AUTOSAR XML (schema 4-2-2)
package /AUTOLIV/SoftwareComponents/CIL
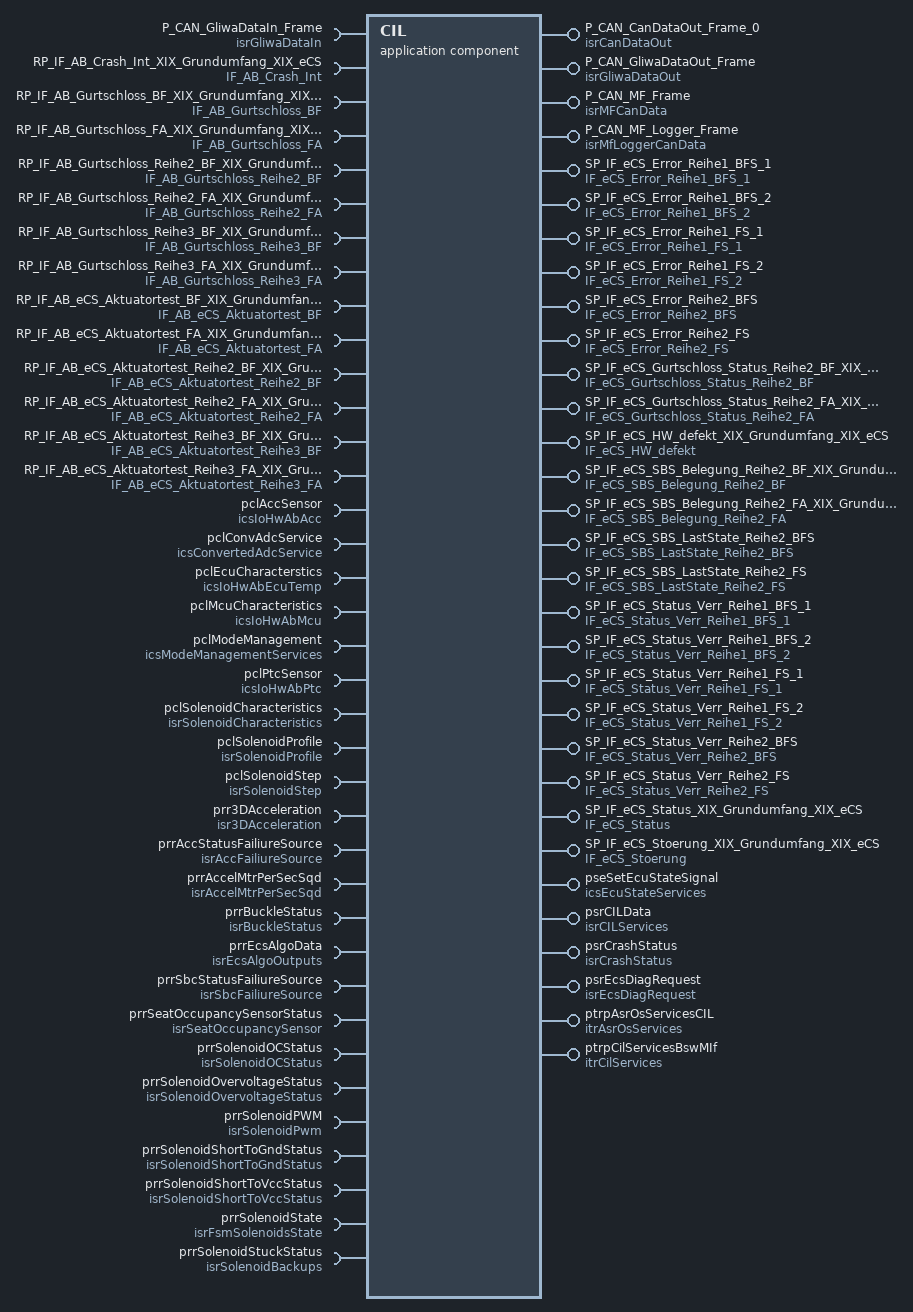
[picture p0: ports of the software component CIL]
  application sw component type CIL: category=SWC
    provide port P_CAN_CanDataOut_Frame_0: nonqueued-sender-com-spec{data-element=EcuCanDataOut, uses-end-to-end-protection=0, init-value=constant-reference=REC_APPLINIT_CAN_DATA_OUT_64}, provided-interface=isrCanDataOut  # # Architecture Element ID ARCH_SW_CIL_P_CAN_CanDataOut_Frame_0 # Description - The runnable shall write all the content of the CAN signals belonging to the eCS Dev Frame - The runnable shall read from the Application the followig data and send them on the CAN bus: - Acceleration on X,Y,Z axis in g - Acceleration on X,Y,Z axis in m/s^2 - eCS Algorithm Decision - Ball Position in mm - Selected Profile[for each solenoid] - Selected step [for each solenoid] - Solenoid state [for each solenoid] - Solenoid confirmation status [for each solenoid] - Buckle Status [for each solenoid] - Lock Execution Counter [for each solenoid] - Unlock Execution Counter [for each solenoid] - Unlock Confirmed Execution Counter [for each solenoid] - Seat Occupancy Status [for each seat] - Warm reset counter # Data Flow ## Inputs: - See data above ## Outputs - See data above # Linked Runnable - CIL_runAppliToCAN # Traceability DOM_eCS_TF_B_114; DOM_eCS_TF_B_117; DOM_eCS_TF_B_119; DOM_eCS_TF_B_124; DOM_eCS_TF_B_126; DOM_eCS_TF_B_129; DOM_eCS_TF_B_135; DOM_eCS_TF_B_137; DOM_eCS_TF_B_139; DOM_eCS_TF_B_141; DOM_eCS_TF_B_143; DOM_eCS_TF_B_145; DOM_eCS_TF_B_149; DOM_eCS_TF_B_152; DOM_eCS_TF_B_155; DOM_eCS_TF_B_157; DOM_eCS_TF_B_159; DOM_eCS_TF_B_161; DOM_eCS_TF_B_163; DOM_eCS_TF_B_165; DOM_eCS_TF_B_169; DOM_eCS_TF_B_171; DOM_eCS_TF_B_173; DOM_eCS_TF_B_175; DOM_eCS_TF_B_177; DOM_eCS_TF_B_178; DOM_eCS_TF_B_179; DOM_eCS_TF_B_545; DOM_eCS_TF_B_560; DOM_eCS_TF_B_557; DOM_eCS_TF_B_554; DOM_eCS_TF_B_551; DOM_eCS_TF_B_548; DOM_eCS_TF_B_563; DOM_eCS_TF_B_579; DOM_eCS_TF_B_575; DOM_eCS_TF_B_572; DOM_eCS_TF_B_569; DOM_eCS_TF_B_566; DOM_eCS_TF_B_581; DOM_eCS_TF_B_596; DOM_eCS_TF_B_593; DOM_eCS_TF_B_590; DOM_eCS_TF_B_587; DOM_eCS_TF_B_584; DOM_eCS_TF_B_614; DOM_eCS_TF_B_611; DOM_eCS_TF_B_608; DOM_eCS_TF_B_605; DOM_eCS_TF_B_602; DOM_eCS_TF_B_599; DOM_eCS_TF_B_617
    require port P_CAN_GliwaDataIn_Frame: nonqueued-receiver-com-spec{data-element=GliwaCanDataIn, init-value=constant-reference=REC_APPLINIT_CAN_DATA}, required-interface=isrGliwaDataIn  # # Architecture Element ID ARCH_SW_CIL_P_CAN_GliwaDataIn_Frame # Description - Interface used to receive {Data on the CAN bus} from the T1 Gliwa suite, if enabled by pre-processor # Data Flow ## Inputs: - ## Outputs - {Data on the CAN bus} # Linked Runnable - CIL_runManageMF # Traceability
    provide port P_CAN_GliwaDataOut_Frame: nonqueued-sender-com-spec{data-element=GliwaCanDataOut, uses-end-to-end-protection=0, init-value=constant-reference=REC_APPLINIT_CAN_DATA_OUT_64}, provided-interface=isrGliwaDataOut  # # Architecture Element ID ARCH_SW_CIL_P_CAN_GliwaDataOut_Frame # Description - The runnable shall be called by the T1 Gliwa library with data that will be sent on the CAN bus, if the pre-processor option is enabled # Data Flow ## Inputs: - ## Outputs - See data above # Linked Runnable - CIL_Gliwa_TXNotification # Traceability
    provide port P_CAN_MF_Frame: nonqueued-sender-com-spec{data-element=stMFData, uses-end-to-end-protection=0, init-value=constant-reference=REC_APPLINIT_CAN_DATA_OUT_64}, provided-interface=isrMFCanData  # P_CAN_MeasurementFrame_Frame | # Architecture Element ID ARCH_SW_CIL_P_CAN_MF_Frame # Description - The runnable shall write all the content of the CAN signals belonging to the eCS Measurement Frame - The runnable shall read from the Application the followig data and send them on the CAN bus: - Multiplexed Block 01: - MCU sensor temperature - ACC sensor temperature - PTC sensor temperature - ECU temperature - PWM applied[for each solenoid] - Voltage measured [for each solenoid] - Current measured mA[for each solenoid] - Solenoid temperature [for each solenoid] - KL30 voltage - Solenoid OC Status[for each solenoid] - Solenoid Short to VBAT Status[for each solenoid] - Solenoid Short to GND Status[for each solenoid] - Solenoid Actuator Blocked Status[for each solenoid] - Accelerometer Error Register Content - SBC Error Register Content - Multiplexed Block 02: - Dem Event Status(for each available event) - Multiplexed Block 03: - Content of RAM memory as configured in the NVP_au32RequestedRamAddressArray, NVP_au8RequestedRamSizeArray variables # Data Flow ## Inputs: - See data above ## Outputs - See data above # Linked Runnable - CIL_runManageMF # Traceability DOM_eCS_TF_B_220; DOM_eCS_TF_B_222; DOM_eCS_TF_B_226; DOM_eCS_TF_B_229; DOM_eCS_TF_B_232; DOM_eCS_TF_B_235; DOM_eCS_TF_B_238; DOM_eCS_TF_B_241; DOM_eCS_TF_B_244; DOM_eCS_TF_B_247; DOM_eCS_TF_B_250; DOM_eCS_TF_B_253; DOM_eCS_TF_B_256; DOM_eCS_TF_B_259; DOM_eCS_TF_B_262; DOM_eCS_TF_B_265; DOM_eCS_TF_B_268; DOM_eCS_TF_B_271; DOM_eCS_TF_B_274; DOM_eCS_TF_B_277; DOM_eCS_TF_B_280; DOM_eCS_TF_B_283; DOM_eCS_TF_B_286; DOM_eCS_TF_B_289; DOM_eCS_TF_B_292; DOM_eCS_TF_B_295; DOM_eCS_TF_B_298; DOM_eCS_TF_B_301; DOM_eCS_TF_B_304; DOM_eCS_TF_B_307; DOM_eCS_TF_B_312; DOM_eCS_TF_B_315; DOM_eCS_TF_B_348; DOM_eCS_TF_B_345; DOM_eCS_TF_B_342; DOM_eCS_TF_B_339; DOM_eCS_TF_B_336; DOM_eCS_TF_B_333; DOM_eCS_TF_B_330; DOM_eCS_TF_B_327; DOM_eCS_TF_B_324; DOM_eCS_TF_B_321; DOM_eCS_TF_B_318; DOM_eCS_TF_B_351; DOM_eCS_TF_B_354
    provide port P_CAN_MF_Logger_Frame: provided-interface=isrMfLoggerCanData  # # Architecture Element ID ARCH_SW_CIL_P_CAN_MF_Logger_Frame # Description - The runnable shall be called when an ECU state change is detected - When an ECU state change is detected then a single frame shall be sent on the CAN bus with the value of the current ECU state # Data Flow ## Inputs: - ## Outputs - {ECU State} # Linked Runnable - CIL_updateCurrentEcuState # Traceability
    13 x require port:
      RP_IF_AB_Crash_Int_XIX_Grundumfang_XIX_eCS: required-interface=IF_AB_Crash_Int  # # Architecture Element ID ARCH_SW_CIL_RP_IF_AB_Crash_Int_XIX_Grundumfang_XIX_eCS # Description - Interface used to receive the crash status from the CAN bus # Data Flow ## Inputs: ## Outputs - {Crash Status} # Linked Runnable - CIL_runAppliToCAN # Traceability DOM_eCS_TF_B_396; DOM_eCS_TF_B_540, DOM_eCS_TF_R_20
      RP_IF_AB_Gurtschloss_BF_XIX_Grundumfang_XIX_eCS: required-interface=IF_AB_Gurtschloss_BF  # # Architecture Element ID ARCH_SW_CIL_RP_IF_AB_Gurtschloss_BF_XIX_Grundumfang_XIX_eCS # Description - Interface used to read the buckle sensor status for the first row # Data Flow ## Inputs: ## Outputs - {Seat Sensor Status} - Can be: LATCHED, NOT_LATCHED, ERROR, NOT_CONFIGURED # Linked Runnable - CIL_runAppliToCAN # Traceability DOM_eCS_TF_B_400, DOM_eCS_TF_R_16
      RP_IF_AB_Gurtschloss_FA_XIX_Grundumfang_XIX_eCS: required-interface=IF_AB_Gurtschloss_FA  # # Architecture Element ID ARCH_SW_CIL_RP_IF_AB_Gurtschloss_FA_XIX_Grundumfang_XIX_eCS # Description - Interface used to read the buckle sensor status for the first row # Data Flow ## Inputs: ## Outputs - {Seat Sensor Status} - Can be: LATCHED, NOT_LATCHED, ERROR, NOT_CONFIGURED # Linked Runnable - CIL_runAppliToCAN # Traceability DOM_eCS_TF_B_403, DOM_eCS_TF_R_17
      RP_IF_AB_Gurtschloss_Reihe2_BF_XIX_Grundumfang_XIX_eCS: required-interface=IF_AB_Gurtschloss_Reihe2_BF  # N/A - Signal not used by Application
      RP_IF_AB_Gurtschloss_Reihe2_FA_XIX_Grundumfang_XIX_eCS: required-interface=IF_AB_Gurtschloss_Reihe2_FA  # N/A - Signal not used by Application
      RP_IF_AB_Gurtschloss_Reihe3_BF_XIX_Grundumfang_XIX_eCS: required-interface=IF_AB_Gurtschloss_Reihe3_BF  # N/A - Signal not used by Application
      RP_IF_AB_Gurtschloss_Reihe3_FA_XIX_Grundumfang_XIX_eCS: required-interface=IF_AB_Gurtschloss_Reihe3_FA  # N/A - Signal not used by Application
      RP_IF_AB_eCS_Aktuatortest_BF_XIX_Grundumfang_XIX_eCS: required-interface=IF_AB_eCS_Aktuatortest_BF  # # Architecture Element ID ARCH_SW_CIL_RP_IF_AB_eCS_Aktuatortest_BF_XIX_Grundumfang_XIX_eCS # Description - Interface used to read if and on demand selt-test has been requested for each solenoid - The on demand self-test for seat BF will trigger the unlock/lock for solenoids 3 && 4 # Data Flow ## Inputs: ## Outputs: - {ODST for Solenoid X} # Linked Runnable - CIL_runCANToSafetyAppli # Traceability DOM_eCS_TF_B_419, DOM_eCS_TF_R_21
      RP_IF_AB_eCS_Aktuatortest_FA_XIX_Grundumfang_XIX_eCS: required-interface=IF_AB_eCS_Aktuatortest_FA  # # Architecture Element ID ARCH_SW_CIL_RP_IF_AB_eCS_Aktuatortest_FA_XIX_Grundumfang_XIX_eCS # Description - Interface used to read if and on demand selt-test has been requested for each solenoid - The on demand self-test for seat FA will trigger the unlock/lock for solenoids 1 && 2 # Data Flow ## Inputs: ## Outputs: - {ODST for Solenoid X} # Linked Runnable - CIL_runCANToSafetyAppli # Traceability DOM_eCS_TF_B_422, DOM_eCS_TF_R_22
      RP_IF_AB_eCS_Aktuatortest_Reihe2_BF_XIX_Grundumfang_XIX_eCS: required-interface=IF_AB_eCS_Aktuatortest_Reihe2_BF  # # Architecture Element ID ARCH_SW_CIL_RP_IF_AB_eCS_Aktuatortest_Reihe2_BF_XIX_Grundumfang_XIX_eCS # Description - Interface used to read if and on demand selt-test has been requested for each solenoid - The on demand self-test for seat BF Reihe 2 will trigger the unlock/lock for solenoids 6 # Data Flow ## Inputs: ## Outputs: - {ODST for Solenoid X} # Linked Runnable - CIL_runCANToSafetyAppli # Traceability DOM_eCS_TF_B_425, DOM_eCS_TF_R_23
      RP_IF_AB_eCS_Aktuatortest_Reihe2_FA_XIX_Grundumfang_XIX_eCS: required-interface=IF_AB_eCS_Aktuatortest_Reihe2_FA  # # Architecture Element ID ARCH_SW_CIL_RP_IF_AB_eCS_Aktuatortest_Reihe2_FA_XIX_Grundumfang_XIX_eCS # Description - Interface used to read if and on demand selt-test has been requested for each solenoid - The on demand self-test for seat FA Reihe 2 will trigger the unlock/lock for solenoids 5 # Data Flow ## Inputs: ## Outputs: - {ODST for Solenoid X} # Linked Runnable - CIL_runCANToSafetyAppli # Traceability DOM_eCS_TF_B_428, DOM_eCS_TF_R_24
      RP_IF_AB_eCS_Aktuatortest_Reihe3_BF_XIX_Grundumfang_XIX_eCS: required-interface=IF_AB_eCS_Aktuatortest_Reihe3_BF  # N/A - Signal not used by Application
      RP_IF_AB_eCS_Aktuatortest_Reihe3_FA_XIX_Grundumfang_XIX_eCS: required-interface=IF_AB_eCS_Aktuatortest_Reihe3_FA  # N/A - Signal not used by Application
    21 x provide port:
      SP_IF_eCS_Error_Reihe1_BFS_1: provided-interface=IF_eCS_Error_Reihe1_BFS_1  # # Architecture Element ID ARCH_SW_CIL_SP_IF_eCS_Error_Reihe1_BFS_1 # Description - The runnable shall read the mode status coresponding to SOLENOID_X_DISABLED where the solenoid is the first one on the front row seat BF - The runnable shall read the error status of the OPEN_CIRCUIT error on the corresponding solenoid - The runnable shall read the error status of the SHORT_TO_GND error on the corresponding solenoid - The runnable shall read the error status of the SHORT_TO_VBAT error on the corresponding solenoid - The runnable shall read the error status of the ACTUATOR_BLOCKED error on the corresponding solenoid - If the SOLENOID_X_DISABLED mode is set and OPEN_CIRCUIT error is set for the corresponding solenoid then the CAN signal shall be set to OPEN_CIRCUIT - If the SOLENOID_X_DISABLED mode is set and SHORT_TO_GND error is set for the corresponding solenoid then the CAN signal shall be set to SHORT_TO_GND - If the SOLENOID_X_DISABLED mode is set and SHORT_TO_VBAT error is set for the corresponding solenoid then the CAN signal shall be set to SHORT_TO_VBAT - If the SOLENOID_X_DISABLED mode is set and ACTUATOR_BLOCKED error is set for the corresponding solenoid then the CAN signal shall be set to ACTUATOR_BLOCKED # Data Flow ## Inputs: - {Mode Status} - {OC Status for Solenoid X} - {Short to VBAT Status for Solenoid X} - {Short to GND Status for Solenoid X} - {Actuator Blocked Status for Solenoid X} ## Outputs - {Error Status} - Can be: NO_ERROR/SHORT_TO_GND/SHORT_TO_VBAT/OPEN_CIRCUIT/ACTUATOR_BLOCKED # Note - ACTUATOR_BLOCKED = ACTUATOR_COIL_ERROR # Linked Runnable - CIL_runAppliToCAN # Traceability DOM_eCS_TF_B_1085
      SP_IF_eCS_Error_Reihe1_BFS_2: provided-interface=IF_eCS_Error_Reihe1_BFS_2  # # Architecture Element ID ARCH_SW_CIL_SP_IF_eCS_Error_Reihe1_BFS_2 # Description - The runnable shall read the mode status coresponding to SOLENOID_X_DISABLED where the solenoid is the second one on the front row seat BF - The runnable shall read the error status of the OPEN_CIRCUIT error on the corresponding solenoid - The runnable shall read the error status of the SHORT_TO_GND error on the corresponding solenoid - The runnable shall read the error status of the SHORT_TO_VBAT error on the corresponding solenoid - The runnable shall read the error status of the ACTUATOR_BLOCKED error on the corresponding solenoid - If the SOLENOID_X_DISABLED mode is set and OPEN_CIRCUIT error is set for the corresponding solenoid then the CAN signal shall be set to OPEN_CIRCUIT - If the SOLENOID_X_DISABLED mode is set and SHORT_TO_GND error is set for the corresponding solenoid then the CAN signal shall be set to SHORT_TO_GND - If the SOLENOID_X_DISABLED mode is set and SHORT_TO_VBAT error is set for the corresponding solenoid then the CAN signal shall be set to SHORT_TO_VBAT - If the SOLENOID_X_DISABLED mode is set and ACTUATOR_BLOCKED error is set for the corresponding solenoid then the CAN signal shall be set to ACTUATOR_BLOCKED # Data Flow ## Inputs: - {Mode Status} - {OC Status for Solenoid X} - {Short to VBAT Status for Solenoid X} - {Short to GND Status for Solenoid X} - {Actuator Blocked Status for Solenoid X} ## Outputs - {Error Status} - Can be: NO_ERROR/SHORT_TO_GND/SHORT_TO_VBAT/OPEN_CIRCUIT/ACTUATOR_BLOCKED # Note - ACTUATOR_BLOCKED = ACTUATOR_COIL_ERROR # Linked Runnable - CIL_runAppliToCAN # Traceability DOM_eCS_TF_B_1089
      SP_IF_eCS_Error_Reihe1_FS_1: provided-interface=IF_eCS_Error_Reihe1_FS_1  # # Architecture Element ID ARCH_SW_CIL_SP_IF_eCS_Error_Reihe1_FS_1 # Description - The runnable shall read the mode status coresponding to SOLENOID_X_DISABLED where the solenoid is the first one on the front row seat FA - The runnable shall read the error status of the OPEN_CIRCUIT error on the corresponding solenoid - The runnable shall read the error status of the SHORT_TO_GND error on the corresponding solenoid - The runnable shall read the error status of the SHORT_TO_VBAT error on the corresponding solenoid - The runnable shall read the error status of the ACTUATOR_BLOCKED error on the corresponding solenoid - If the SOLENOID_X_DISABLED mode is set and OPEN_CIRCUIT error is set for the corresponding solenoid then the CAN signal shall be set to OPEN_CIRCUIT - If the SOLENOID_X_DISABLED mode is set and SHORT_TO_GND error is set for the corresponding solenoid then the CAN signal shall be set to SHORT_TO_GND - If the SOLENOID_X_DISABLED mode is set and SHORT_TO_VBAT error is set for the corresponding solenoid then the CAN signal shall be set to SHORT_TO_VBAT - If the SOLENOID_X_DISABLED mode is set and ACTUATOR_BLOCKED error is set for the corresponding solenoid then the CAN signal shall be set to ACTUATOR_BLOCKED # Data Flow ## Inputs: - {Mode Status} - {OC Status for Solenoid X} - {Short to VBAT Status for Solenoid X} - {Short to GND Status for Solenoid X} - {Actuator Blocked Status for Solenoid X} ## Outputs - {Error Status} - Can be: NO_ERROR/SHORT_TO_GND/SHORT_TO_VBAT/OPEN_CIRCUIT/ACTUATOR_BLOCKED # Note - ACTUATOR_BLOCKED = ACTUATOR_COIL_ERROR # Linked Runnable - CIL_runAppliToCAN # Traceability DOM_eCS_TF_B_1065
      SP_IF_eCS_Error_Reihe1_FS_2: provided-interface=IF_eCS_Error_Reihe1_FS_2  # # Architecture Element ID ARCH_SW_CIL_SP_IF_eCS_Error_Reihe1_FS_2 # Description - The runnable shall read the mode status coresponding to SOLENOID_X_DISABLED where the solenoid is the second one on the front row seat FA - The runnable shall read the error status of the OPEN_CIRCUIT error on the corresponding solenoid - The runnable shall read the error status of the SHORT_TO_GND error on the corresponding solenoid - The runnable shall read the error status of the SHORT_TO_VBAT error on the corresponding solenoid - The runnable shall read the error status of the ACTUATOR_BLOCKED error on the corresponding solenoid - If the SOLENOID_X_DISABLED mode is set and OPEN_CIRCUIT error is set for the corresponding solenoid then the CAN signal shall be set to OPEN_CIRCUIT - If the SOLENOID_X_DISABLED mode is set and SHORT_TO_GND error is set for the corresponding solenoid then the CAN signal shall be set to SHORT_TO_GND - If the SOLENOID_X_DISABLED mode is set and SHORT_TO_VBAT error is set for the corresponding solenoid then the CAN signal shall be set to SHORT_TO_VBAT - If the SOLENOID_X_DISABLED mode is set and ACTUATOR_BLOCKED error is set for the corresponding solenoid then the CAN signal shall be set to ACTUATOR_BLOCKED # Data Flow ## Inputs: - {Mode Status} - {OC Status for Solenoid X} - {Short to VBAT Status for Solenoid X} - {Short to GND Status for Solenoid X} - {Actuator Blocked Status for Solenoid X} ## Outputs - {Error Status} - Can be: NO_ERROR/SHORT_TO_GND/SHORT_TO_VBAT/OPEN_CIRCUIT/ACTUATOR_BLOCKED # Note - ACTUATOR_BLOCKED = ACTUATOR_COIL_ERROR # Linked Runnable - CIL_runAppliToCAN # Traceability DOM_eCS_TF_B_1087
      SP_IF_eCS_Error_Reihe2_BFS: provided-interface=IF_eCS_Error_Reihe2_BFS  # # Architecture Element ID ARCH_SW_CIL_SP_IF_eCS_Error_Reihe2_BFS # Description - The runnable shall read the mode status coresponding to SOLENOID_X_DISABLED where the solenoid is the one on the second row seat BF - The runnable shall read the error status of the OPEN_CIRCUIT error on the corresponding solenoid - The runnable shall read the error status of the SHORT_TO_GND error on the corresponding solenoid - The runnable shall read the error status of the SHORT_TO_VBAT error on the corresponding solenoid - The runnable shall read the error status of the ACTUATOR_BLOCKED error on the corresponding solenoid - If the SOLENOID_X_DISABLED mode is set and OPEN_CIRCUIT error is set for the corresponding solenoid then the CAN signal shall be set to OPEN_CIRCUIT - If the SOLENOID_X_DISABLED mode is set and SHORT_TO_GND error is set for the corresponding solenoid then the CAN signal shall be set to SHORT_TO_GND - If the SOLENOID_X_DISABLED mode is set and SHORT_TO_VBAT error is set for the corresponding solenoid then the CAN signal shall be set to SHORT_TO_VBAT - If the SOLENOID_X_DISABLED mode is set and ACTUATOR_BLOCKED error is set for the corresponding solenoid then the CAN signal shall be set to ACTUATOR_BLOCKED # Data Flow ## Inputs: - {Mode Status} - {OC Status for Solenoid X} - {Short to VBAT Status for Solenoid X} - {Short to GND Status for Solenoid X} - {Actuator Blocked Status for Solenoid X} ## Outputs - {Error Status} - Can be: NO_ERROR/SHORT_TO_GND/SHORT_TO_VBAT/OPEN_CIRCUIT/ACTUATOR_BLOCKED # Note - ACTUATOR_BLOCKED = ACTUATOR_COIL_ERROR # Linked Runnable - CIL_runAppliToCAN # Traceability DOM_eCS_TF_B_1093
      SP_IF_eCS_Error_Reihe2_FS: provided-interface=IF_eCS_Error_Reihe2_FS  # # Architecture Element ID ARCH_SW_CIL_SP_IF_eCS_Error_Reihe2_FS # Description - The runnable shall read the mode status coresponding to SOLENOID_X_DISABLED where the solenoid is the one on the second row seat FA - The runnable shall read the error status of the OPEN_CIRCUIT error on the corresponding solenoid - The runnable shall read the error status of the SHORT_TO_GND error on the corresponding solenoid - The runnable shall read the error status of the SHORT_TO_VBAT error on the corresponding solenoid - The runnable shall read the error status of the ACTUATOR_BLOCKED error on the corresponding solenoid - If the SOLENOID_X_DISABLED mode is set and OPEN_CIRCUIT error is set for the corresponding solenoid then the CAN signal shall be set to OPEN_CIRCUIT - If the SOLENOID_X_DISABLED mode is set and SHORT_TO_GND error is set for the corresponding solenoid then the CAN signal shall be set to SHORT_TO_GND - If the SOLENOID_X_DISABLED mode is set and SHORT_TO_VBAT error is set for the corresponding solenoid then the CAN signal shall be set to SHORT_TO_VBAT - If the SOLENOID_X_DISABLED mode is set and ACTUATOR_BLOCKED error is set for the corresponding solenoid then the CAN signal shall be set to ACTUATOR_BLOCKED # Data Flow ## Inputs: - {Mode Status} - {OC Status for Solenoid X} - {Short to VBAT Status for Solenoid X} - {Short to GND Status for Solenoid X} - {Actuator Blocked Status for Solenoid X} ## Outputs - {Error Status} - Can be: NO_ERROR/SHORT_TO_GND/SHORT_TO_VBAT/OPEN_CIRCUIT/ACTUATOR_BLOCKED # Note - ACTUATOR_BLOCKED = ACTUATOR_COIL_ERROR # Linked Runnable - CIL_runAppliToCAN # Traceability DOM_eCS_TF_B_1091
      SP_IF_eCS_Gurtschloss_Status_Reihe2_BF_XIX_Grundumfang_XIX_eCS: provided-interface=IF_eCS_Gurtschloss_Status_Reihe2_BF  # # Architecture Element ID ARCH_SW_CIL_SP_IF_eCS_Gurtschloss_Status_Reihe2_BF_XIX_Grundumfang_XIX_eCS # Description - The runnable shall read the buckle sensor status from the IoHwAb module - The runnable shall write the buckle sensor status for the second row on the CAN bus - If the input parameter is LATCHED then it shall transmit the LATCHED value on the CAN bus - If the input parameter is NOT_LATCHED then it shall transmit the NOT_LATCHED value on the CAN bus - If the input parameter is UNKNOWN then it shall transmit the ERROR/NOT_AVAILABLE value on the CAN bus - If the buckle sensor is not configured via the NVP_u32eCSVariant variable then the NOT_CONFIGURED value will be sent on the CAN bus # Data Flow ## Inputs: - {Buckle Sensor Status} - Can be: LATCHED, NOT_LATCHED, UNKNOWN ## Outputs - {Buckle Sensor Status} - Can be: LATCHED, NOT_LATCHED, ERROR/NOT_AVAILABLE, NOT_CONFIGURED # Linked Runnable - CIL_runAppliToCAN # Traceability DOM_eCS_TF_B_450
      SP_IF_eCS_Gurtschloss_Status_Reihe2_FA_XIX_Grundumfang_XIX_eCS: provided-interface=IF_eCS_Gurtschloss_Status_Reihe2_FA  # # Architecture Element ID ARCH_SW_CIL_SP_IF_eCS_Gurtschloss_Status_Reihe2_FA_XIX_Grundumfang_XIX_eCS # Description - The runnable shall read the buckle sensor status from the IoHwAb module - The runnable shall write the buckle sensor status for the second row on the CAN bus - If the input parameter is LATCHED then it shall transmit the LATCHED value on the CAN bus - If the input parameter is NOT_LATCHED then it shall transmit the NOT_LATCHED value on the CAN bus - If the input parameter is UNKNOWN then it shall transmit the ERROR/NOT_AVAILABLE value on the CAN bus - If the buckle sensor is not configured via the NVP_u32eCSVariant variable then the NOT_CONFIGURED value will be sent on the CAN bus # Data Flow ## Inputs: - {Buckle Sensor Status} - Can be: LATCHED, NOT_LATCHED, UNKNOWN ## Outputs - {Buckle Sensor Status} - Can be: LATCHED, NOT_LATCHED, ERROR/NOT_AVAILABLE, NOT_CONFIGURED # Linked Runnable - CIL_runAppliToCAN # Traceability DOM_eCS_TF_B_453, DOM_eCS_TF_B_497
      SP_IF_eCS_HW_defekt_XIX_Grundumfang_XIX_eCS: provided-interface=IF_eCS_HW_defekt  # # Architecture Element ID ARCH_SW_CIL_SP_IF_eCS_HW_defekt_XIX_Grundumfang_XIX_eCS # Description - The runnable shall read the mode status coresponding to KU32_ECU_SPORADIC_ERROR - If the KU32_ECU_SPORADIC_ERROR mode is set then the signal shall be set to ERROR_PRESENT - If the KU32_ECU_SPORADIC_ERROR mode is not set then the signal shall be set to ERROR_NOT_PRESENT # Data Flow ## Inputs: - {Mode Status} ## Outputs - {Error Status} - Can be: ERROR_PRESENT, ERROR_NOT_PRESENT # Linked Runnable - CIL_runAppliToCAN # Traceability DOM_eCS_TF_B_530, DOM_eCS_TF_B_458, DOM_eCS_TF_B_538, DOM_eCS_TF_B_623
      SP_IF_eCS_SBS_Belegung_Reihe2_BF_XIX_Grundumfang_XIX_eCS: provided-interface=IF_eCS_SBS_Belegung_Reihe2_BF  # # Architecture Element ID ARCH_SW_CIL_SP_IF_eCS_SBS_Belegung_Reihe2_BF_XIX_Grundumfang_XIX_eCS # Description - The runnable shall read the buckle and seat sensor status from the IoHwAb module - If the seat sensor is not configured for seat BF row 2 then the {Seat Status for Seat BF on row 2} shall be set to NICHT_VERBAUT - If the seat is occupied for seat BF row 2 then the {Seat Status for Seat BF on row 2} shall be set to BELEGT - If the seat is not occupied for seat BF row 2 then the {Seat Status for Seat BF on row 2} shall be set to NICHT_BELEGT # Data Flow ## Inputs: - {Configuration Option for Seat Sensor Seat BF row 2} - {Seat Status for Seat BF on row 2} - Can be KU8_SEAT_OCCUPANCY_NOT_DETECTED, KU8_SEAT_OCCUPANCY_DETECTED, KU8_SEAT_OCCUPANCY_UNKNOWN ## Outputs - {Seat Status for Seat BF on row 2} - Can be NICHT_BELEGT, BELEGT, KURZSCHLUSS_NACH_MASSE, NICHT_VERBAUT # Linked Runnable - CIL_runAppliToCAN # Traceability DOM_eCS_TF_B_464
      SP_IF_eCS_SBS_Belegung_Reihe2_FA_XIX_Grundumfang_XIX_eCS: provided-interface=IF_eCS_SBS_Belegung_Reihe2_FA  # # Architecture Element ID ARCH_SW_CIL_SP_IF_eCS_SBS_Belegung_Reihe2_FA_XIX_Grundumfang_XIX_eCS # Description - The runnable shall read the buckle and seat sensor status from the IoHwAb module - If the seat sensor is not configured for seat FA row 2 then the {Seat Status for Seat FA on row 2} shall be set to NICHT_VERBAUT - If the seat is occupied for seat FA row 2 then the {Seat Status for Seat FA on row 2} shall be set to BELEGT - If the seat is not occupied for seat FA row 2 then the {Seat Status for Seat FA on row 2} shall be set to NICHT_BELEGT # Data Flow ## Inputs: - {Configuration Option for Seat Sensor Seat FA row 2} - {Seat Status for Seat FA on row 2} - Can be KU8_SEAT_OCCUPANCY_NOT_DETECTED, KU8_SEAT_OCCUPANCY_DETECTED, KU8_SEAT_OCCUPANCY_UNKNOWN ## Outputs - {Seat Status for Seat FA on row 2} - Can be NICHT_BELEGT, BELEGT, KURZSCHLUSS_NACH_MASSE, NICHT_VERBAUT # Linked Runnable - CIL_runAppliToCAN # Traceability DOM_eCS_TF_B_497, DOM_eCS_TF_B_467
      SP_IF_eCS_SBS_LastState_Reihe2_BFS: provided-interface=IF_eCS_SBS_LastState_Reihe2_BFS  # # Architecture Element ID ARCH_SW_CIL_SP_IF_eCS_SBS_LastState_Reihe2_BFS # Description - The runnable shall write the last valid state of the SBS coresponding to the second seat on the second row - The runnable shall return OCCUPIED if the last valid state was OCCUPIED - The runnable shall return NOT_OCCUPIED if the last valid state was NOT_OCCUPIED - The runnable shall return INIT if the NvM was not initialized - The runnable shall return ERROR if the last valid state was SHORT_TO_GND and removable seats are not configured via the NVP_u32eCSVariant variable - The runnable shall return ERROR if the last valid state was IMPLAUSIBLE # Data Flow ## Inputs: - {Internal last valid SBS State} - {SBS configuration} ## Outputs - {Last Valid SBS Status} - Can be INIT/OCCUPIED/NOT_OCCUPIED/ERROR # Linked Runnable - CIL_runAppliToCAN # Traceability DOM_eCS_TF_B_1096, DOM_eCS_TF_B_1150
      SP_IF_eCS_SBS_LastState_Reihe2_FS: provided-interface=IF_eCS_SBS_LastState_Reihe2_FS  # # Architecture Element ID ARCH_SW_CIL_SP_IF_eCS_SBS_LastState_Reihe2_FS # Description - The runnable shall write the last valid state of the SBS coresponding to the first seat on the second row - The runnable shall return OCCUPIED if the last valid state was OCCUPIED - The runnable shall return NOT_OCCUPIED if the last valid state was NOT_OCCUPIED - The runnable shall return INIT if the NvM was not initialized - The runnable shall return ERROR if the last valid state was SHORT_TO_GND and removable seats are not configured via the NVP_u32eCSVariant variable - The runnable shall return ERROR if the last valid state was IMPLAUSIBLE # Data Flow ## Inputs: - {Internal last valid SBS State} - {SBS configuration} ## Outputs - {Last Valid SBS Status} - Can be INIT/OCCUPIED/NOT_OCCUPIED/ERROR # Linked Runnable - CIL_runAppliToCAN # Traceability DOM_eCS_TF_B_1083, DOM_eCS_TF_B_1149
      SP_IF_eCS_Status_Verr_Reihe1_BFS_1: provided-interface=IF_eCS_Status_Verr_Reihe1_BFS_1  # # Architecture Element ID ARCH_SW_CIL_SP_IF_eCS_Status_Verr_Reihe1_BFS_1 # Description - The runnable shall write the state of the first solenoid coresponding to the front row seat BF - The runnable shall read the NvM confiration for the solenoid in order to determine if it is configured - The runnable shall read the critical auto-test status via the mode management interface - The runnable shall read the SOLENOID_X_DISABLED status via the mode management interface - The runnable shall read the current state of the solenoid - The runnable shall read the current output of the virtual ball algorithm - If the critical auto-tests have not been run then the INIT value shall be transmitted on the CAN Bus - If the SOLENOID_X_DISABLED mask is set then the ERROR value shall be transmitted on the CAN Bus - If the solenoid is not configured in NvM the NOT_CONFIGURED value shall be transmitted on the CAN bus - If the current solenoid state is LOCK then the LOCK state then this value shall be transmitted on the CAN bus - If the current solenoid state is UNLOCK/BACKUP then the LOCK state then this value shall be transmitted on the CAN bus - If the current solenoid state is STARTUP/DIAGNOSTIC then the solenoid state shall be transmitted either LOCK or UNLOCK depending on the output of the virtual ball algo # Data Flow ## Inputs: - {Solenoid Configuration in NvM} - {Critical Auto-test status} - {Solenoid_X_Disabled error status} - {Ball algo output} - {Solenoid_X_State} ## Outputs - {Solenoid Status} - Can be INIT-ERROR/LOCK/UNLOCK/NOT_CONFIGURED # Note - NOT_CONFIGURED = NOT_INSTALLED # Linked Runnable - CIL_runAppliToCAN # Traceability DOM_eCS_TF_B_1050
      SP_IF_eCS_Status_Verr_Reihe1_BFS_2: provided-interface=IF_eCS_Status_Verr_Reihe1_BFS_2  # # Architecture Element ID ARCH_SW_CIL_SP_IF_eCS_Status_Verr_Reihe1_BFS_2 # Description - The runnable shall write the state of the second solenoid coresponding to the front row seat BF - The runnable shall read the NvM confiration for the solenoid in order to determine if it is configured - The runnable shall read the critical auto-test status via the mode management interface - The runnable shall read the SOLENOID_X_DISABLED status via the mode management interface - The runnable shall read the current state of the solenoid - The runnable shall read the current output of the virtual ball algorithm - If the critical auto-tests have not been run then the INIT value shall be transmitted on the CAN Bus - If the SOLENOID_X_DISABLED mask is set then the ERROR value shall be transmitted on the CAN Bus - If the solenoid is not configured in NvM the NOT_CONFIGURED value shall be transmitted on the CAN bus - If the current solenoid state is LOCK then the LOCK state then this value shall be transmitted on the CAN bus - If the current solenoid state is UNLOCK/BACKUP then the LOCK state then this value shall be transmitted on the CAN bus - If the current solenoid state is STARTUP/DIAGNOSTIC then the solenoid state shall be transmitted either LOCK or UNLOCK depending on the output of the virtual ball algo # Data Flow ## Inputs: - {Solenoid Configuration in NvM} - {Critical Auto-test status} - {Solenoid_X_Disabled error status} - {Ball algo output} - {Solenoid_X_State} ## Outputs - {Solenoid Status} - Can be INIT-ERROR/LOCK/UNLOCK/NOT_CONFIGURED # Note - NOT_CONFIGURED = NOT_INSTALLED # Linked Runnable - CIL_runAppliToCAN # Traceability DOM_eCS_TF_B_1056
      SP_IF_eCS_Status_Verr_Reihe1_FS_1: provided-interface=IF_eCS_Status_Verr_Reihe1_FS_1  # # Architecture Element ID ARCH_SW_CIL_SP_IF_eCS_Status_Verr_Reihe1_FS_1 # Description - The runnable shall write the state of the first solenoid coresponding to the front row seat FA - The runnable shall read the NvM confiration for the solenoid in order to determine if it is configured - The runnable shall read the critical auto-test status via the mode management interface - The runnable shall read the SOLENOID_X_DISABLED status via the mode management interface - The runnable shall read the current state of the solenoid - The runnable shall read the current output of the virtual ball algorithm - If the critical auto-tests have not been run then the INIT value shall be transmitted on the CAN Bus - If the SOLENOID_X_DISABLED mask is set then the ERROR value shall be transmitted on the CAN Bus - If the solenoid is not configured in NvM the NOT_CONFIGURED value shall be transmitted on the CAN bus - If the current solenoid state is LOCK then the LOCK state then this value shall be transmitted on the CAN bus - If the current solenoid state is UNLOCK/BACKUP then the LOCK state then this value shall be transmitted on the CAN bus - If the current solenoid state is STARTUP/DIAGNOSTIC then the solenoid state shall be transmitted either LOCK or UNLOCK depending on the output of the virtual ball algo # Data Flow ## Inputs: - {Solenoid Configuration in NvM} - {Critical Auto-test status} - {Solenoid_X_Disabled error status} - {Ball algo output} - {Solenoid_X_State} ## Outputs - {Solenoid Status} - Can be INIT-ERROR/LOCK/UNLOCK/NOT_CONFIGURED #Note - NOT_CONFIGURED = NOT_INSTALLED # Linked Runnable - CIL_runAppliToCAN # Traceability DOM_eCS_TF_B_1045
      SP_IF_eCS_Status_Verr_Reihe1_FS_2: provided-interface=IF_eCS_Status_Verr_Reihe1_FS_2  # # Architecture Element ID ARCH_SW_CIL_SP_IF_eCS_Status_Verr_Reihe1_FS_2 # Description - The runnable shall write the state of the second solenoid coresponding to the front row seat FA - The runnable shall read the NvM confiration for the solenoid in order to determine if it is configured - The runnable shall read the critical auto-test status via the mode management interface - The runnable shall read the SOLENOID_X_DISABLED status via the mode management interface - The runnable shall read the current state of the solenoid - The runnable shall read the current output of the virtual ball algorithm - If the critical auto-tests have not been run then the INIT value shall be transmitted on the CAN Bus - If the SOLENOID_X_DISABLED mask is set then the ERROR value shall be transmitted on the CAN Bus - If the solenoid is not configured in NvM the NOT_CONFIGURED value shall be transmitted on the CAN bus - If the current solenoid state is LOCK then the LOCK state then this value shall be transmitted on the CAN bus - If the current solenoid state is UNLOCK/BACKUP then the LOCK state then this value shall be transmitted on the CAN bus - If the current solenoid state is STARTUP/DIAGNOSTIC then the solenoid state shall be transmitted either LOCK or UNLOCK depending on the output of the virtual ball algo # Data Flow ## Inputs: - {Solenoid Configuration in NvM} - {Critical Auto-test status} - {Solenoid_X_Disabled error status} - {Ball algo output} - {Solenoid_X_State} ## Outputs - {Solenoid Status} - Can be INIT-ERROR/LOCK/UNLOCK/NOT_CONFIGURED # Note - NOT_CONFIGURED = NOT_INSTALLED # Linked Runnable - CIL_runAppliToCAN # Traceability DOM_eCS_TF_B_1053
      SP_IF_eCS_Status_Verr_Reihe2_BFS: provided-interface=IF_eCS_Status_Verr_Reihe2_BFS  # # Architecture Element ID ARCH_SW_CIL_SP_IF_eCS_Status_Verr_Reihe2_BFS # Description - The runnable shall write the state of the solenoid coresponding to the second row seat BF - The runnable shall read the NvM confiration for the solenoid in order to determine if it is configured - The runnable shall read the critical auto-test status via the mode management interface - The runnable shall read the SOLENOID_X_DISABLED status via the mode management interface - The runnable shall read the current state of the solenoid - The runnable shall read the current output of the virtual ball algorithm - If the critical auto-tests have not been run then the INIT value shall be transmitted on the CAN Bus - If the SOLENOID_X_DISABLED mask is set then the ERROR value shall be transmitted on the CAN Bus - If the solenoid is not configured in NvM the NOT_CONFIGURED value shall be transmitted on the CAN bus - If the current solenoid state is LOCK then the LOCK state then this value shall be transmitted on the CAN bus - If the current solenoid state is UNLOCK/BACKUP then the LOCK state then this value shall be transmitted on the CAN bus - If the current solenoid state is STARTUP/DIAGNOSTIC then the solenoid state shall be transmitted either LOCK or UNLOCK depending on the output of the virtual ball algo # Data Flow ## Inputs: - {Solenoid Configuration in NvM} - {Critical Auto-test status} - {Solenoid_X_Disabled error status} - {Ball algo output} - {Solenoid_X_State} # Note - NOT_CONFIGURED = NOT_INSTALLED ## Outputs - {Solenoid Status} - Can be INIT-ERROR/LOCK/UNLOCK/NOT_CONFIGURED # Linked Runnable - CIL_runAppliToCAN # Traceability DOM_eCS_TF_B_1062
      SP_IF_eCS_Status_Verr_Reihe2_FS: provided-interface=IF_eCS_Status_Verr_Reihe2_FS  # # Architecture Element ID ARCH_SW_CIL_SP_IF_eCS_Status_Verr_Reihe2_FS # Description - The runnable shall write the state of the solenoid coresponding to the second row seat FA - The runnable shall read the NvM confiration for the solenoid in order to determine if it is configured - The runnable shall read the critical auto-test status via the mode management interface - The runnable shall read the SOLENOID_X_DISABLED status via the mode management interface - The runnable shall read the current state of the solenoid - The runnable shall read the current output of the virtual ball algorithm - If the critical auto-tests have not been run then the INIT value shall be transmitted on the CAN Bus - If the SOLENOID_X_DISABLED mask is set then the ERROR value shall be transmitted on the CAN Bus - If the solenoid is not configured in NvM the NOT_CONFIGURED value shall be transmitted on the CAN bus - If the current solenoid state is LOCK then the LOCK state then this value shall be transmitted on the CAN bus - If the current solenoid state is UNLOCK/BACKUP then the LOCK state then this value shall be transmitted on the CAN bus - If the current solenoid state is STARTUP/DIAGNOSTIC then the solenoid state shall be transmitted either LOCK or UNLOCK depending on the output of the virtual ball algo # Data Flow ## Inputs: - {Solenoid Configuration in NvM} - {Critical Auto-test status} - {Solenoid_X_Disabled error status} - {Ball algo output} - {Solenoid_X_State} ## Outputs - {Solenoid Status} - Can be INIT-ERROR/LOCK/UNLOCK/NOT_CONFIGURED # Note - NOT_CONFIGURED = NOT_INSTALLED # Linked Runnable - CIL_runAppliToCAN # Traceability DOM_eCS_TF_B_1059
      SP_IF_eCS_Status_XIX_Grundumfang_XIX_eCS: provided-interface=IF_eCS_Status  # # Architecture Element ID ARCH_SW_CIL_SP_IF_eCS_Status_XIX_Grundumfang_XIX_eCS # Description - The runnable shall write the status of the eCS ECU on the CAN bus - The runnable shall read the current output of the virtual ball algorithm - The runnable shall read the critical auto-test status via the mode management interface - The runnable shall read the permanent and sporadic error status via the mode management interface - If the critical auto-tests have not been run then the INIT value shall be transmitted on the CAN Bus - If the permanent HW error mode is set then the ERROR value shall be transmitted on the CAN Bus - If the sporadic error mode is set then the ERROR value shall be transmitted on the CAN Bus - If the ball algorithm outputs the LOCK state then this value shall be transmitted on the CAN bus - If the ball algorithm outputs the UNLOCK state then this value shall be transmitted on the CAN bus # Data Flow ## Inputs: - {Critical Auto-test status} - {Permanent HW error status} - {Sporadic error status} - {Ball algo output} ## Outputs - {eCS Status} - Can be INIT/ERROR/LOCK/UNLOCK # Linked Runnable - CIL_runAppliToCAN # Traceability DOM_eCS_TF_B_499; DOM_eCS_TF_B_470;DOM_eCS_TF_B_1035
      SP_IF_eCS_Stoerung_XIX_Grundumfang_XIX_eCS: provided-interface=IF_eCS_Stoerung  # # Architecture Element ID ARCH_SW_CIL_SP_IF_eCS_Stoerung_XIX_Grundumfang_XIX_eCS # Description - The runnable shall read the mode status coresponding to KU32_ECU_PERMANENT_HW_ERROR - If the KU32_ECU_PERMANENT_HW_ERROR mode is set then the signal shall be set to ERROR_PRESENT - If the KU32_ECU_PERMANENT_HW_ERROR mode is not set then the signal shall be set to ERROR_NOT_PRESENT # Data Flow ## Inputs: - {Mode Status} ## Outputs - {Error Status} - Can be: ERROR_PRESENT, ERROR_NOT_PRESENT # Linked Runnable - CIL_runAppliToCAN # Traceability DOM_eCS_TF_B_461, DOM_eCS_TF_B_539
    23 x require port:
      pclAccSensor: client-com-spec=GetTemperature, required-interface=icsIoHwAbAcc  # # Architecture Element ID ARCH_SW_CIL_pclAccSensor # Description - Interface used to receive temperature for the accelerometer sensor # Data Flow ## Inputs: ## Outputs - {Sensor Temperature} - Value in *C # Linked Runnable - CIL_runManageMF # Traceability
      pclConvAdcService: client-com-spec=getMeasure, required-interface=icsConvertedAdcService  # # Architecture Element ID ARCH_SW_CIL_pclConvAdcService # Description - Interface is used to read physical measurements in SI units - Interface will be used to read the voltage (mV) on each solenoid - Interface will be used to read the current (mA) on each solenoid # Data Flow ## Inputs: ## Outputs: - {SI Measurement} # Linked Runnable - CIL_runManageMF # Traceability
      pclEcuCharacterstics: client-com-spec=GetTemperature, required-interface=icsIoHwAbEcuTemp  # # Architecture Element ID ARCH_SW_CIL_pclEcuCharacterstics # Description - Interface used to receive the temperature of the ECU PCB # Data Flow ## Inputs: ## Outputs - {ECU temperature in *C} # Linked Runnable - CIL_runManageMF # Traceability
      pclMcuCharacteristics: client-com-spec=GetTemperature, required-interface=icsIoHwAbMcu  # # Architecture Element ID ARCH_SW_CIL_pclMcuCharacteristics # Description - Interface used to read the temperature of the MCU in *C # Data Flow ## Inputs: ## Outputs -{MCU Temperature} # Linked Runnable - CIL_runManageMF # Traceability
      pclModeManagement: client-com-spec=CheckModeStatus, required-interface=icsModeManagementServices  # # Architecture Element ID ARCH_SW_CIL_pclModeManagement # Description - The interface shall used to read the mode status in order to determine if the critical auto-tests have been run - The interface shall be used to read the mode status in order to determine if the solenoids are disabled (error present) - The interface shall be used to read the mode status in order to determine if a permanent HW error is present - The interface shall be used to read the mode status in order to determine if a sporadic error is present - The interface shall be used to read the mode status in order to determine if the solenoid lever has reached the unlock position - The {Mode Status Mask} shall be passed as an input parameter to select which mode is being checked # Data Flow ## Inputs: - {Mode Status Mask} - Can be: KU32_ECU_PERMANENT_HW_ERROR, KU32_ECU_SPORADIC_ERROR, KU32_SOLENOID_x_UNLOCK_CONFIRMED, KU32_CRITICAL_AUTOTESTS_IN_PROGRESS, KU32_SOLENOID_x_DISABLED ## Outputs - {Autotest Result} - {Mode Status} - Can be B_TRUE, B_FALSE # Linked Runnable - CIL_runAppliToCAN # Traceability DOM_eCS_TF_B_1108, DOM_eCS_TF_B_1109, DOM_eCS_TF_B_1110, DOM_eCS_TF_B_1111, DOM_eCS_TF_B_1112, DOM_eCS_TF_B_1113, DOM_eCS_TF_B_1114, DOM_eCS_TF_B_1115, DOM_eCS_TF_B_1116, DOM_eCS_TF_B_1117, DOM_eCS_TF_B_1118, DOM_eCS_TF_B_1098, DOM_eCS_TF_B_1099, DOM_eCS_TF_B_1100, DOM_eCS_TF_B_1102, DOM_eCS_TF_B_1105, DOM_eCS_TF_B_1106, DOM_eCS_TF_B_1147, DOM_eCS_TF_B_1036, DOM_eCS_TF_B_1144
      pclPtcSensor: client-com-spec=GetTemperature, required-interface=icsIoHwAbPtc  # # Architecture Element ID ARCH_SW_CIL_pclPtcSensor # Description - Function used to get the output temperature of the resistor sensor and then transmit it to CAN # Data Flow ## Inputs: ## Outputs - {Temperature in *C} # Linked Runnable - CIL_runManageMF # Traceability
      pclSolenoidCharacteristics: client-com-spec=GetTemperature, required-interface=isrSolenoidCharacteristics  # # Architecture Element ID ARCH_SW_CIL_pclSolenoidCharacteristics # Description - This interface read the solenoid temperature # Data Flow ## Inputs: ## Outputs - {Solenoid Temperature in *C} # Linked Runnable - CIL_runManageMF # Traceability
      pclSolenoidProfile: nonqueued-receiver-com-spec{data-element=au8SelectedProfile, init-value=6 x KU8_PROFILE_UNLOCK}, required-interface=isrSolenoidProfile  # # Architecture Element ID ARCH_SW_CIL_pclSolenoidProfile # Description - Function used to read the currently executed profile for each solenoid # Data Flow ## Inputs: ## Outputs - {Currently Executed Profile for Solenoid x} # Linked Runnable - CIL_runAppliToCAN # Traceability
      pclSolenoidStep: nonqueued-receiver-com-spec{data-element=au8CurrentStep, init-value=6 x 0}, required-interface=isrSolenoidStep  # # Architecture Element ID ARCH_SW_CIL_pclSolenoidStep # Description - Interface used to read solenoid current step for each solenoid # Data Flow ## Inputs: ## Outputs: - {Current Executed Step} # Linked Runnable - CIL_runAppliToCAN # Traceability
      prr3DAcceleration: nonqueued-receiver-com-spec{data-element=st3DAccel, init-value=fields=[0, 0, 0]}, required-interface=isr3DAcceleration  # # Architecture Element ID ARCH_SW_CIL_prr3DAcceleration # Description - Function used to read Raw Acceleration in g from SPI communication # Data Flow ## Inputs: ## Outputs - {Raw acceleration} in g # Linked Runnable - CIL_runAppliToCAN # Traceability
      prrAccStatusFailiureSource: required-interface=isrAccFailiureSource  # # Architecture Element ID ARCH_SW_CIL_prrAccStatusFailiureSource # Description - Interface is used to read the source of the ALARM pin that is set by the accelerometer and send it on the CAN bus # Data Flow ## Inputs: ## Outputs - {ACC register alarm status} - {ACC CRC status} - {ACC return status} # Linked Runnable - CIL_runManageMF # Traceability
        required-com-specs:
          data-element=u32AccAlarmRegStatus, init-value=0
          data-element=u8AccCRCStatus, init-value=0
          data-element=u8AccReturnStatus, init-value=0
          data-element=u8AccelAxisBroken, init-value=0
          data-element=u8AccAlarmbPreinitSeqStatus, init-value=0
      prrAccelMtrPerSecSqd: nonqueued-receiver-com-spec{data-element=stAccelMtrPerSecSqd, init-value=fields=[0, 0, 0]}, required-interface=isrAccelMtrPerSecSqd  # # Architecture Element ID ARCH_SW_CIL_prrAccelMtrPerSecSqd # Description - Function used to read the acceleration converted to m/s^2 from the SPI communication # Data Flow ## Inputs: ## Outputs - {Raw acceleration} in m/s^2 # Linked Runnable - CIL_runAppliToCAN # Traceability
      prrBuckleStatus: nonqueued-receiver-com-spec{data-element=au8BuckleStatus, init-value=[KU8_BUCKLE_LATCHED, KU8_BUCKLE_LATCHED]}, required-interface=isrBuckleStatus  # # Architecture Element ID ARCH_SW_CIL_prrBuckleStatus # Description - Interface used to read the buckle sensor status for the second row # Data Flow ## Inputs: ## Outputs - {Seat Sensor Status} - Can be: KU8_BUCKLE_NOT_LATCHED, KU8_BUCKLE_LATCHED, KU8_BUCKLE_UNKNOWN # Linked Runnable - CIL_runAppliToCAN # Traceability
      prrEcsAlgoData: required-com-specs=[{data-element=u8EcsFlag, init-value=KU8_ECS_ALGO_LOCK}, {data-element=u16BallPosition, init-value=0}], required-interface=isrEcsAlgoOutputs  # # Architecture Element ID ARCH_SW_CIL_prrEcsAlgoData_b8EcsFlag # Description - Interface used to read the virtual ball algorithm output # Data Flow ## Inputs: ## Outputs - {Algo Output} - EcsFlag can be UNLOCK or LOCK # Linked Runnable - CIL_runAppliToCAN # Traceability --------------------------------------------------------------------- # Architecture Element ID ARCH_SW_CIL_prrEcsAlgoData_u16BallPosition # Description - Interface used to read algo ball position in mm # Data Flow ## Inputs: - {Ball Position} ## Outputs # Linked Runnable - CIL_runAppliToCAN # Traceability
      prrSbcStatusFailiureSource: nonqueued-receiver-com-spec{data-element=u32SbcReg1Status, init-value=0}, required-interface=isrSbcFailiureSource  # # Architecture Element ID ARCH_SW_CIL_prrSbcStatusFailiureSource # Description - Interface is used to read the error source on the SBC and send it on the CAN bus # Data Flow ## Inputs: ## Outputs - {SBC register failiure status} # Linked Runnable - CIL_runManageMF # Traceability
      prrSeatOccupancySensorStatus: nonqueued-receiver-com-spec{data-element=au8SeatOccupancySensorStatus, init-value=[KU8_SEAT_OCCUPANCY_DETECTED, KU8_SEAT_OCCUPANCY_DETECTED]}, required-interface=isrSeatOccupancySensor  # # Architecture Element ID ARCH_SW_CIL_prrSeatOccupancySensorStatus # Description - Interface used to read the seat sensor status for the second row # Data Flow ## Inputs: ## Outputs - {Seat Sensor Status} - Can be: KU8_SEAT_OCCUPANCY_NOT_DETECTED, KU8_SEAT_OCCUPANCY_DETECTED, KU8_SEAT_OCCUPANCY_UNKNOWN # Linked Runnable - CIL_runAppliToCAN # Traceability
      prrSolenoidOCStatus: nonqueued-receiver-com-spec{data-element=au8SolenoidAutotestStatus, init-value=6 x KU8_SOLENOID_ELECTRICAL_AT_PASSED}, required-interface=isrSolenoidOCStatus  # # Architecture Element ID ARCH_SW_CIL_prrSolenoidOCStatus # Description - Interface is used to read the source(which solenoid is faulty) for qualification of the SOLENOID_OC auto-test and send it on the CAN bus # Data Flow ## Inputs: ## Outputs - {Open Circuit status for Solenoid x} # Linked Runnable - CIL_runAppliToCAN - CIL_runManageMF # Traceability DOM_eCS_TF_B_1121, DOM_eCS_TF_B_1125, DOM_eCS_TF_B_1129, DOM_eCS_TF_B_1134, DOM_eCS_TF_B_1138, DOM_eCS_TF_B_1142
      prrSolenoidOvervoltageStatus: nonqueued-receiver-com-spec{data-element=au8SolenoidOvervoltageStatus, init-value=6 x KU8_SOLENOID_ELECTRICAL_AT_PASSED}, required-interface=isrSolenoidOvervoltageStatus  # # Architecture Element ID ARCH_SW_CIL_prrSolenoidOvervoltageStatus # Description - Interface is used to read the source(which solenoid is faulty) for qualification of the SOLENOID_OVERVOLTAGE auto-test and send it on the CAN bus # Data Flow ## Inputs: ## Outputs - {SOLENOID OVERVOLTAGE status for Solenoid x} # Linked Runnable - CIL_runAppliToCAN - CIL_runManageMF # Traceability DOM_eCS_TF_B_1121, DOM_eCS_TF_B_1125, DOM_eCS_TF_B_1129, DOM_eCS_TF_B_1134, DOM_eCS_TF_B_1138, DOM_eCS_TF_B_1142
      prrSolenoidPWM: nonqueued-receiver-com-spec{data-element=au16Pwm, init-value=6 x 0}, required-interface=isrSolenoidPwm  # # Architecture Element ID ARCH_SW_CIL_prrSolenoidPWM # Description - Interface used to read the PWM applied on each solenoid # Data Flow ## Inputs: ## Outputs - {PWM Command} # Linked Runnable - CIL_runManageMF # Traceability
      prrSolenoidShortToGndStatus: nonqueued-receiver-com-spec{data-element=au8SolenoidAutotestStatus, init-value=6 x KU8_SOLENOID_ELECTRICAL_AT_PASSED}, required-interface=isrSolenoidShortToGndStatus  # # Architecture Element ID ARCH_SW_CIL_prrSolenoidShortToGndStatus # Description - Interface is used to read the source(which solenoid is faulty) for qualification of the SHORT_TO_GND auto-test and send it on the CAN bus # Data Flow ## Inputs: ## Outputs - {Short To GND status for Solenoid x} # Linked Runnable - CIL_runAppliToCAN - CIL_runManageMF # Traceability DOM_eCS_TF_B_1119, DOM_eCS_TF_B_1123, DOM_eCS_TF_B_1127, DOM_eCS_TF_B_1132, DOM_eCS_TF_B_1136, DOM_eCS_TF_B_1140
      prrSolenoidShortToVccStatus: nonqueued-receiver-com-spec{data-element=au8SolenoidAutotestStatus, init-value=6 x KU8_SOLENOID_ELECTRICAL_AT_PASSED}, required-interface=isrSolenoidShortToVccStatus  # # Architecture Element ID ARCH_SW_CIL_prrSolenoidShortToVccStatus # Description - Interface is used to read the source(which solenoid is faulty) for qualification of the SHORT_TO_VCC auto-test and send it on the CAN bus # Data Flow ## Inputs: ## Outputs - {Short To VCC status for Solenoid x} # Linked Runnable - CIL_runAppliToCAN - CIL_runManageMF # Note - SHORT_TO_VCC = SHORT_TO_VBAT # Traceability DOM_eCS_TF_B_1120, DOM_eCS_TF_B_1124, DOM_eCS_TF_B_1128, DOM_eCS_TF_B_1133, DOM_eCS_TF_B_1137, DOM_eCS_TF_B_1141
      prrSolenoidState: nonqueued-receiver-com-spec{data-element=au8SolenoidState, init-value=6 x KU8_LOCK_STATE}, required-interface=isrFsmSolenoidsState  # # Architecture Element ID ARCH_SW_CIL_prrSolenoidState # Description - Interface that read the state for each solenoid # Data Flow ## Inputs: ## Outputs - {Solenoid State} # Linked Runnable - CIL_runAppliToCAN # Traceability
      prrSolenoidStuckStatus: nonqueued-receiver-com-spec{data-element=au8SolenoidIsStuck, handle-never-received=true, init-value=6 x 0}, required-interface=isrSolenoidBackups  # # Architecture Element ID ARCH_SW_CIL_prrSolenoidStuckStatus # Description - Interface is used to read the stauts of each solenoid regarding if the actuator is stuck or not. # Data Flow ## Inputs ## Outputs - {Solenoid Stuck Status} - Can be KU8_FALSE - if the solenoid is NOT stuck; - Can be KU8_TRUE - if the solenoid is stuck; # Linked Runnable - CIL_runManageMF # Traceability DOM_eCS_TF_B_1122, DOM_eCS_TF_B_1126, DOM_eCS_TF_B_1130, DOM_eCS_TF_B_1135, DOM_eCS_TF_B_1139, DOM_eCS_TF_B_1143
    6 x provide port:
      pseSetEcuStateSignal: server-com-spec{operation=updateCurrentEcuState, queue-length=1}, provided-interface=icsEcuStateServices  # # Architecture Element ID ARCH_SW_CIL_pseSetEcuStateSignal # Description - The CIL_updateCurrentEcuState shall be called in order to set the current status ECU State. # Data Flow ## Inputs: - {Current Ecu State} ## Outputs: - None # Linked Runnable - CIL_updateCurrentEcuState # Traceability
      psrCILData: nonqueued-sender-com-spec{data-element=au8MergedBuckleStatus, uses-end-to-end-protection=0, init-value=6 x KU8_BUCKLE_LATCHED}, provided-interface=isrCILServices  # # Architecture Element ID ARCH_SW_CIL_psrCILData_au8MergedBuckleStatus # Description - This interface shall provide the merged buckle status coresponding to each solenoid as follows: - Seat FA buckle switch (CAN bus) to solenoid 1 and 2 - Seat BF buckle switch (CAN bus) to solenoid 3 and 4 - Wake Line 1 buckle switch to solenoid 5 - Wake Line 6 buckle switch to solenoid 5 # Data Flow ## Inputs: - {Buckle Status received on the CAN bus} - {Buckle Status read from the Wake lines} ## Outputs - {Buckle Status for each solenoid) # Linked Runnable - CIL_runAppliToCAN # Traceability
      psrCrashStatus: nonqueued-sender-com-spec{data-element=u8IsCrashActive, uses-end-to-end-protection=0, init-value=CM_AB_Crash_Int_Cx0_kein_Crash}, provided-interface=isrCrashStatus  # # Architecture Element ID ARCH_SW_CIL_psrCrashStatus_u8IsCrashActive # Description - Interface used to transmit the crash status to the rest of the Application - The solenoids will be locked if a crash situation has been detected(any value other than NO_CRASH) # Data Flow ## Inputs: ## Outputs - {Crash Status} # Linked Runnable - CIL_runCANToSafetyAppli # Traceability DOM_eCS_TF_B_540
      psrEcsDiagRequest: provided-interface=isrEcsDiagRequest  # # Architecture Element ID ARCH_SW_CIL_psrEcsDiagRequest # Description - The runnable shall write the interface in order to trigger an unlock/lock for a certain solenoid - The runnable shall trigger the UNLOCK of solenoids 1 and 2 if t he UNLOCK value is received on the actuator test corresponding to seat FA - The runnable shall trigger the LOCK of solenoids 1 and 2 if the LOCK value is received on the actuator test corresponding to seat FA - The runnable shall trigger the UNLOCK of solenoids 3 and 4 if the UNLOCK value is received on the actuator test corresponding to seat BF - The runnable shall trigger the LOCK of solenoids 3 and 4 if the LOCK value is received on the actuator test corresponding to seat BF - The runnable shall trigger the UNLOCK of solenoid 5 if the UNLOCK value is received on the actuator test corresponding to seat FA on the second row - The runnable shall trigger the LOCK of solenoid 5 if t he LOCK value is received on the actuator test corresponding to seat FA on the second row - The runnable shall trigger the UNLOCK of solenoid 6 if the UNLOCK value is received on the actuator test corresponding to seat BF on the second row - The runnable shall trigger the LOCK of solenoid 6 if the LOCK value is received on the actuator test corresponding to seat BF on the second row # Data Flow ## Inputs: - {On demand self-test} ## Outputs - {Solenoid Command} - Can be UNLOCK/LOCK/NO_REQUEST - {Solenoid Command Complement} - Can be ~UNLOCK/~LOCK/~NO_REQUEST # Linked Runnable - CIL_runCANToSafetyAppli # Traceability DOM_eCS_TF_B_493, DOM_eCS_TF_B_440, DOM_eCS_TF_B_494,DOM_eCS_TF_B_443, DOM_eCS_TF_B_495, DOM_eCS_TF_B_445,DOM_eCS_TF_B_496, DOM_eCS_TF_B_447
        provided-com-specs:
          data-element=au8DiagReq, uses-end-to-end-protection=0, init-value=6 x KU8_NO_DIAG_REQUEST
          data-element=au8DiagReqComplement, uses-end-to-end-protection=0, init-value=6 x KU8_NO_DIAG_REQUEST_COMPLEMENT
      ptrpAsrOsServicesCIL: provided-interface=itrAsrOsServices  # # Architecture Element ID ARCH_SW_CIL_ptrpAsrOsServicesCIL_CIL_runCANToAppli # Description - Runnable shall be called by the Autosar OS each 10ms # Data Flow ## Inputs: ## Outputs # Linked Runnable - CIL_runCANToAppli # Traceability --------------------------------------------------------------------------------------- # Architecture Element ID ARCH_SW_CIL_ptrpAsrOsServicesCIL_CIL_runAppliToCAN # Description - Runnable shall be called by the Autosar OS each 2ms # Data Flow ## Inputs: ## Outputs # Linked Runnable - CIL_runAppliToCAN # Traceability --------------------------------------------------------------------------------------- # Architecture Element ID ARCH_SW_CIL_ptrpAsrOsServicesCIL_CIL_runCANToSafetyAppli # Description - Runnable shall be called by the Autosar OS each 10ms # Data Flow ## Inputs: ## Outputs # Linked Runnable - CIL_runCANToSafetyAppli # Traceability
      ptrpCilServicesBswMIf: provided-interface=itrCilServices  # # Architecture Element ID ARCH_SW_Cil_ptrpCilServicesBswMIf_CIL_runInit # Description - The CIL_runInit runnable shall be called during the initialization in the BswM_OnStartComEffective runnable # Data Flow # Linked Runnable - CIL_runInit # Traceability
  application array data type au8MergedBuckleStatusType_Appl: category=ARRAY
    element elem_au8MergedBuckleStatusType_Appl: category=VALUE, type=u8MergedBuckleStatusType_Appl, array-size-semantics=FIXED-SIZE, max-number-of-elements=6
  sender receiver interface isrCILServices
    data au8MergedBuckleStatus: type=au8MergedBuckleStatusType_Appl, init-value=6 x KU8_BUCKLE_LATCHED
  sender receiver interface isrCrashStatus
    data u8IsCrashActive: type=u8AbCrashIntType_Appl
